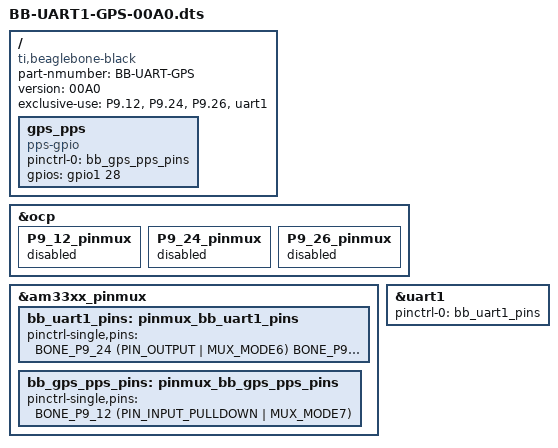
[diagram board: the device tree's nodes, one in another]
/*
 *
 * Virtual cape for UART1 on connector pins P9.24 P9.26 w/PPS on P9.12
 * 
 * Based on this thread:
 *   https://forum.beagleboard.org/t/beaglebone-black-gps-pps-and-chrony-for-time-sync/897/17
 */

/dts-v1/;
/plugin/;

#include <dt-bindings/board/am335x-bbw-bbb-base.h>
#include <dt-bindings/gpio/gpio.h>
#include <dt-bindings/pinctrl/am33xx.h>

/{
    compatible = "ti,beaglebone-black";

    part-nmumber = "BB-UART-GPS";
    version = "00A0";

    exclusive-use = "P9.12", "P9.24", "P9.26", "uart1";

    fragment@0 {
        target=<&ocp>;
        __overlay__ {
            P9_12_pinmux{status="disabled";};
            P9_24_pinmux{status="disabled";};
            P9_26_pinmux{status="disabled";};
        };
    };

    fragment@1 {
        target = <&am33xx_pinmux>;
        __overlay__ {
            bb_uart1_pins: pinmux_bb_uart1_pins {
                pinctrl-single,pins = <
                    BONE_P9_24 (PIN_OUTPUT | MUX_MODE6)	// uart1_txd.uart1_txd
                    BONE_P9_26 (PIN_INPUT | MUX_MODE6)	// uart1_rxd.uart1_rxd
                >;
            };

            bb_gps_pps_pins: pinmux_bb_gps_pps_pins {
                pinctrl-single,pins = <
                    BONE_P9_12 (PIN_INPUT_PULLDOWN | MUX_MODE7)	
                >;
            };
        };
    };

    fragment@2 {
        target = <&uart1>;
        __overlay__ {
            status = "okay";
            pinctrl-names = "default";
            pinctrl-0 = <&bb_uart1_pins>;
        };
    };

    fragment@3 {
        target-path = "/";
        __overlay__ {
            gps_pps {
                status = "okay";
                compatible = "pps-gpio";
                pinctrl-names = "default";
                pinctrl-0 = <&bb_gps_pps_pins>;
                gpios = <&gpio1 28 0>;
            }; 
        };
    };
};
